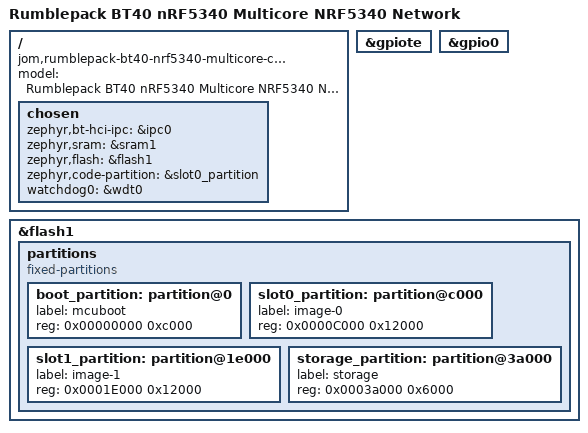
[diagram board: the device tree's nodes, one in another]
/*
 * Copyright (c) 2020 Nordic Semiconductor ASA
 *
 * SPDX-License-Identifier: Apache-2.0
 */

/dts-v1/;
#include <nordic/nrf5340_cpunet_qkaa.dtsi>
#include "rumblepack_bt40_nrf5340_multicore_cpunet-pinctrl.dtsi"

/ {
	model = "Rumblepack BT40 nRF5340 Multicore NRF5340 Network";
	compatible = "jom,rumblepack-bt40-nrf5340-multicore-cpunet";

	chosen {
		zephyr,bt-hci-ipc = &ipc0;
		zephyr,sram = &sram1;
		zephyr,flash = &flash1;
		zephyr,code-partition = &slot0_partition;
		watchdog0 = &wdt0;
	};

};

&gpiote {
	status = "okay";
};

&gpio0 {
	status = "okay";
};

&flash1 {

	partitions {
		compatible = "fixed-partitions";
		#address-cells = <1>;
		#size-cells = <1>;

		boot_partition: partition@0 {
			label = "mcuboot";
			reg = <0x00000000 0xc000>;
		};
		slot0_partition: partition@c000 {
			label = "image-0";
			reg = <0x0000C000 0x12000>;
		};
		slot1_partition: partition@1e000 {
			label = "image-1";
			reg = <0x0001E000 0x12000>;
		};
		storage_partition: partition@3a000 {
			label = "storage";
			reg = <0x0003a000 0x6000>;
		};
	};
};

/* Include shared RAM configuration file */
#include "rumblepack_bt40_nrf5340_multicore_shared_sram_planning_conf.dtsi"
#include "rumblepack_bt40_nrf5340_multicore_shared.dtsi"
